# YT9215 register map
Vendor: Motorcomm; Series: YT921x; File version: 1.0
Registers are 32-bit, read-write, no defined reset value unless marked. A register's access mark holds for its fields unless they carry their own. Offsets are from the block's base; [hi:lo] are bit positions; lines under a group give offsets from that group; {n}, {i} and the like mark numbered series; 'fields as' and 'values as' point back to an identical list.

## L2 — Layer 2 forwarding and VLAN table
Base 0x00180000
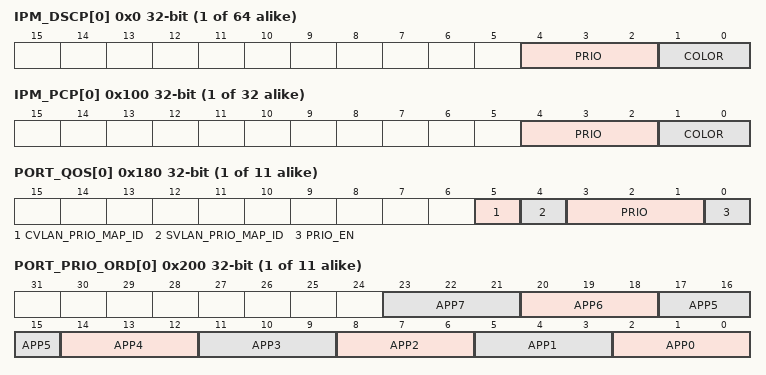
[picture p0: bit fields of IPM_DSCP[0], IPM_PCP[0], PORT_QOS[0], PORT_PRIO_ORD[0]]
{0x0+4i} IPM_DSCP[{i}] (i=0..63) — Internal priority and colour for each of the 64 IP DSCP values. Index: dscp = 0 to 63.
  [4:2] PRIO — Internal priority from 0 to 7.
  [1:0] COLOR — Drop precedence colour. It is inferred from METER_CTRL.COLOR_BLIND that the meters use it.
    0=GREEN (Lowest drop precedence); 1=YELLOW; 2=RED (Highest drop precedence)
{0x100+4i} IPM_PCP[{i}] (i=0..31) — Internal priority and colour for each VLAN tag priority. There are two maps (index map); each has one entry per drop eligible bit value (dei) and priority code point (pcp). The vendor SDK functions fal_tiger_qos_intPri_cpri_map_set() and fal_tiger_qos_intPri_spri_map_set() write a fixed map number to PORT_QOS and use it as the index map: 0 for the customer tag and 1 for the service tag. Index: map = 0 to 1, dei = 0 to 1, pcp = 0 to 7. Flat index = 16 × map + 8 × dei + pcp.
  fields as IPM_DSCP[0]
{0x180+4i} PORT_QOS[{i}] (i=0..10) — Port default priority and, by the code of the vendor SDK that the description of IPM_PCP names, the choice of IPM_PCP map. Index: port = 0 to 10.
  [5] CVLAN_PRIO_MAP_ID — Index map of the IPM_PCP map used for customer tags.
  [4] SVLAN_PRIO_MAP_ID — Index map of the IPM_PCP map used for service tags.
  [3:1] PRIO — Port default priority from 0 to 7.
  [0] PRIO_EN — Enables the port default priority.
{0x200+4i} PORT_PRIO_ORD[{i}] (i=0..10) — Ranks the sources of a frame's internal priority on one port. Each source has a 3-bit weight. It is inferred that the source with the highest non-zero weight that applies to the frame wins; a comment in yt_qos.h of the vendor SDK reads "The higher the value, the higher the priority". Priority sources lists the source numbers. Index: port = 0 to 10.
  [3n+2:3n] APP{n} (n=0..7) — Weight of priority source app. 0 disables the source, except for the port default priority which is enabled by PORT_QOS.PRIO_EN.
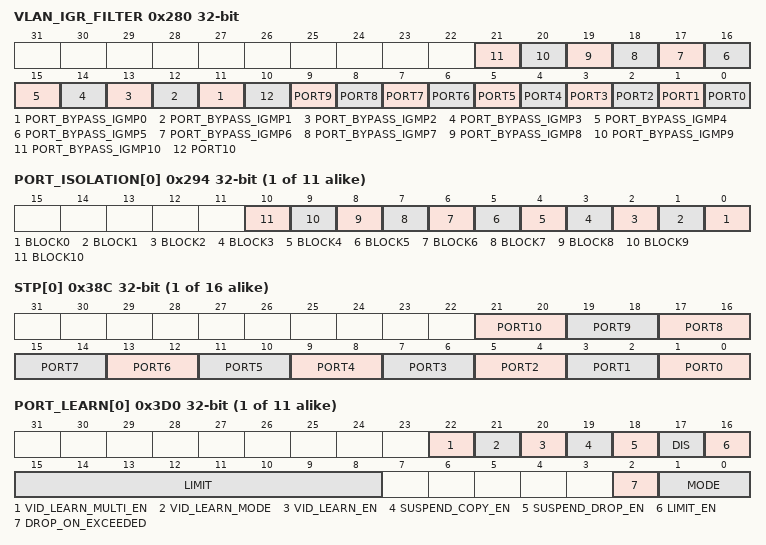
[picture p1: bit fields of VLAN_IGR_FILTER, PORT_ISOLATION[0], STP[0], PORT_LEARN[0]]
0x280 VLAN_IGR_FILTER — Per-port ingress VLAN membership check.
  [n+11] PORT_BYPASS_IGMP{n} (n=0..10) — IGMP frames received on port port skip the ingress membership check.
  [n] PORT{n} (n=0..10) — Port port receives frames only of VLANs that list it.
{0x294+4i} PORT_ISOLATION[{i}] (i=0..10) — Destination ports that frames received on one port must not be sent to. This is the mechanism that separates ports into groups; see Port isolation. Index: port = 0 to 10.
  [n] BLOCK{n} (n=0..10) — Frames received on this port are never sent to port port.
{0x38C+4i} STP[{i}] (i=0..15) — Port states of one spanning tree instance, two bits per port. A VLAN chooses its instance with VLAN_CTRL.STP_ID. Index: inst = 0 to 15.
  [2n+1:2n] PORT{n} (n=0..10) — State of port port in this instance.
    0=DISABLED (Port neither forwards nor learns); 1=LEARNING (Port learns addresses but does not forward); 2=BLOCKING (Port neither forwards nor learns. It is inferred from IEEE 802.1D that the port receives bridge protocol frames); 3=FORWARD (Port forwards and learns)
{0x3D0+4i} PORT_LEARN[{i}] (i=0..10) — Controls learning of source addresses on one port. Index: port = 0 to 10.
  [22] VID_LEARN_MULTI_EN — Function not known.
  [21] VID_LEARN_MODE — Function not known.
  [20] VID_LEARN_EN — Function not known.
  [19] SUSPEND_COPY_EN — Copy frames with a not yet learned source address to the CPU.
  [18] SUSPEND_DROP_EN — Drop frames with a not yet learned source address.
  [17] DIS — Disables address learning on the port.
  [16] LIMIT_EN — Enables the limit in PORT_LEARN.LIMIT.
  [15:8] LIMIT — Largest number of addresses learned on the port. The vendor SDK lists this field as 13 bits wide, at bits 15 to 3.
  [2] DROP_ON_EXCEEDED — Drop frames with a new source address once the limit is reached.
  [1:0] MODE — Who learns addresses.
    0=AUTO (The switch learns by itself); 1=AUTO_AND_COPY (The switch learns and copies the frame to the CPU); 2=CPU_CONTROL (Only the CPU adds entries)
0x440 AGEING — Time base of forwarding database ageing.
  [15:0] INTERVAL — Ageing time in units of 5 seconds.
0x454 FDB_IN0 — First input word of a forwarding database command; see Forwarding database.
  [31:0] ADDR_HI4 — MAC address bytes 0 to 3. Byte 0 is in bits 31 to 24.
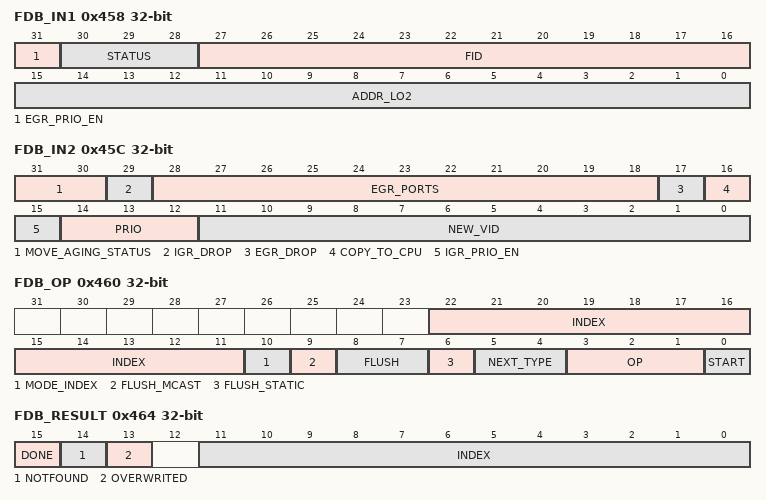
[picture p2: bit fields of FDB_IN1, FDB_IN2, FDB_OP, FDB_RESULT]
0x458 FDB_IN1 — Second input word of a forwarding database command.
  [31] EGR_PRIO_EN — Apply the priority of the entry to frames sent to this address.
  [30:28] STATUS — State of the entry.
    0=INVALID (Entry is empty); 1=MIN_TIME (Dynamic entry about to age out); 3=MOVE_AGING_MAX_TIME (Dynamic entry that moved to another port); 5=MAX_TIME (Dynamic entry just learned or refreshed); 6=PENDING (Entry waiting for the CPU to confirm it); 7=STATIC (Static entry that never ages out)
  [27:16] FID — Filtering ID of the entry. The Linux driver uses the VLAN ID as the filtering ID.
  [15:0] ADDR_LO2 — MAC address bytes 4 and 5. Byte 4 is in bits 15 to 8.
0x45C FDB_IN2 — Third input word of a forwarding database command.
  [31:30] MOVE_AGING_STATUS — Ageing state of an entry that moved between ports.
  [29] IGR_DROP — Drop frames received from this address.
  [28:18] EGR_PORTS — Ports that frames to this address are sent to. Each port has one bit.
  [17] EGR_DROP — Drop frames sent to this address.
  [16] COPY_TO_CPU — Also copy frames to this address to the CPU.
  [15] IGR_PRIO_EN — Apply FDB_IN2.PRIO to frames received from this address.
  [14:12] PRIO — Priority given by this entry. It is a source for PORT_PRIO_ORD.
  [11:0] NEW_VID — Replacement VLAN ID for frames matching the entry.
0x460 FDB_OP — Selects and starts a forwarding database command. Write the input words first, then this register with FDB_OP.START set, then wait for FDB_RESULT.DONE.
  [22:11] INDEX — Entry index from 0 to 4095. It is used when FDB_OP.MODE_INDEX is set.
  [10] MODE_INDEX — Addresses the entry by FDB_OP.INDEX. Value 0 addresses it by MAC address and filtering ID.
  [9] FLUSH_MCAST — A flush removes multicast entries in place of unicast entries. The vendor SDK list yt_l2_tbl_op_flush_mode_t gives this meaning to the bit.
  [8:7] FLUSH — Scope of a flush.
    0=ALL (Every entry of the kind that FDB_OP.FLUSH_MCAST selects); 1=PORT (Entries of the ports in FDB_IN2.EGR_PORTS); 2=PORT_VID (Entries of the ports in FDB_IN2.EGR_PORTS with the filtering ID in FDB_IN1.FID); 3=VID (Entries with the filtering ID in FDB_IN1.FID)
  [6] FLUSH_STATIC — A flush also removes static entries.
  [5:4] NEXT_TYPE — Which entries FDB_OP.OP.GET_NEXT walks.
    0=UCAST_PORT (Unicast entries of one port); 1=UCAST_VID (Unicast entries of one filtering ID); 2=UCAST (All unicast entries); 3=MCAST (Multicast entries)
  [3:1] OP — Command.
    0=ADD (Write an entry); 1=DEL (Delete an entry); 2=GET_ONE (Read one entry); 3=GET_NEXT (Read the next used entry after FDB_OP.INDEX); 4=FLUSH (Delete many entries)
  [0] START — Write 1 to start the command.
0x464 FDB_RESULT ro — Completion flag and outcome of the last FDB_OP command.
  [15] DONE — 1 when the command has finished.
  [14] NOTFOUND — No entry matched.
  [13] OVERWRITED — The command overwrote an existing entry.
  [11:0] INDEX — Index of the entry the command acted on.
0x4B0 FDB_OUT0 ro — First word of the entry read by a FDB_OP.OP.GET_ONE or FDB_OP.OP.GET_NEXT command.
  fields as FDB_IN0
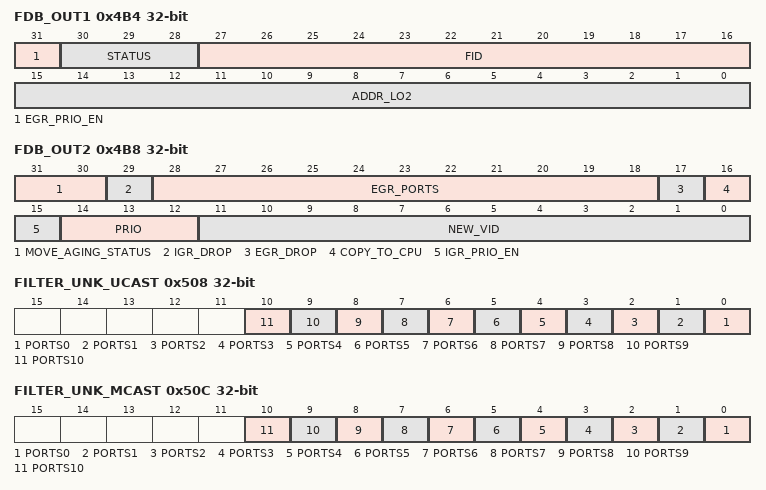
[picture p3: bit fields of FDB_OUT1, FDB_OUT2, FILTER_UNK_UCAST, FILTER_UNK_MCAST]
0x4B4 FDB_OUT1 ro — Second word of the entry read by a FDB_OP.OP.GET_ONE or FDB_OP.OP.GET_NEXT command.
  fields as FDB_IN1
0x4B8 FDB_OUT2 ro — Third word of the entry read by a FDB_OP.OP.GET_ONE or FDB_OP.OP.GET_NEXT command.
  [31:30] MOVE_AGING_STATUS — Ageing state of an entry that moved between ports.
  [29] IGR_DROP — Drop frames received from this address.
  [28:18] EGR_PORTS — Ports that frames to this address are sent to. Each port has one bit.
  [17] EGR_DROP — Drop frames sent to this address.
  [16] COPY_TO_CPU — Also copy frames to this address to the CPU.
  [15] IGR_PRIO_EN — Apply FDB_OUT2.PRIO to frames received from this address.
  [14:12] PRIO — Priority given by this entry. It is a source for PORT_PRIO_ORD.
  [11:0] NEW_VID — Replacement VLAN ID for frames matching the entry.
0x508 FILTER_UNK_UCAST — Port mask for flooded frames with an unknown unicast destination. yt921x_chip_setup_dsa sets the bit of every port.
  [n] PORTS{n} (n=0..10) — It is inferred from the word "filter" in the register name that frames of this class are not flooded to port port while its bit is set.
0x50C FILTER_UNK_MCAST — Port mask for flooded frames with an unknown multicast destination. yt921x_chip_setup_dsa sets the bit of every port.
  fields as FILTER_UNK_UCAST
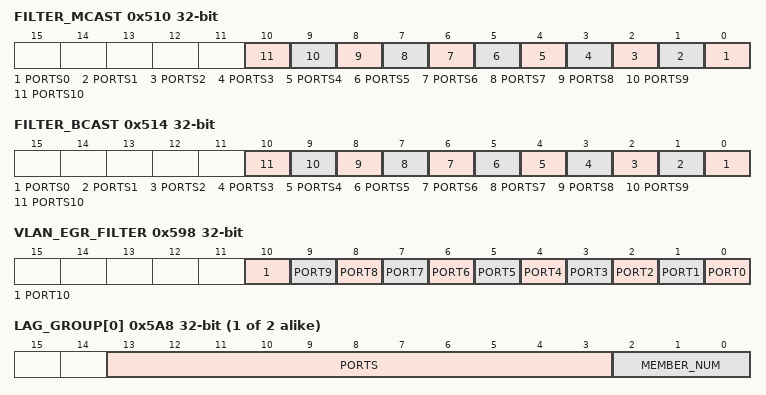
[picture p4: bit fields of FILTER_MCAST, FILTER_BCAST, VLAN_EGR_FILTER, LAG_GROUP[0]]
0x510 FILTER_MCAST — Ports that do not receive multicast frames.
  fields as FILTER_UNK_UCAST
0x514 FILTER_BCAST — Ports that do not receive broadcast frames.
  fields as FILTER_UNK_UCAST
0x598 VLAN_EGR_FILTER — Per-port egress VLAN membership check.
  [n] PORT{n} (n=0..10) — Port port sends frames only of VLANs that list it.
{0x5A8+4i} LAG_GROUP[{i}] (i=0..1) — Member ports and member count of one link aggregation group. Index: lag = 0 to 1.
  [13:3] PORTS — Member ports. Each port has one bit.
  [2:0] MEMBER_NUM — Number of valid LAG_MEMBER slots of the group.
{0x5B0+4i} LAG_MEMBER[{i}] (i=0..7) — Port in one of the four member slots of a group. The hash result picks a slot. Index: lag = 0 to 1, slot = 0 to 3. Flat index = 4 × lag + slot.
  [3:0] PORT — Port number in this slot.
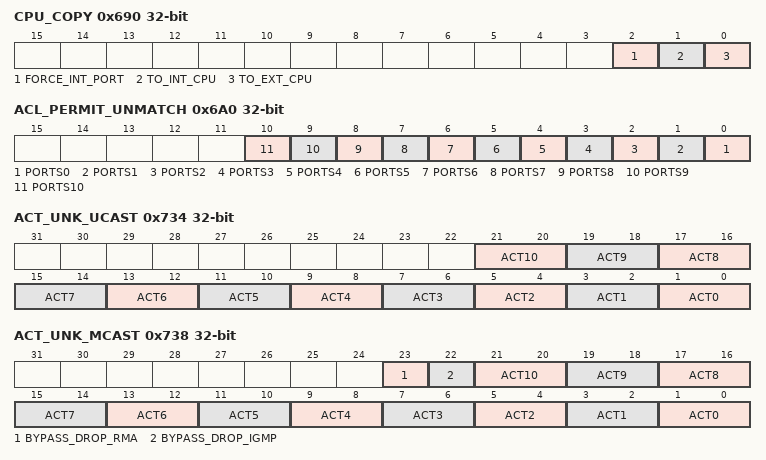
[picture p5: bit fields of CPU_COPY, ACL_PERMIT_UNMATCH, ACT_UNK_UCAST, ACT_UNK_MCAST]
0x690 CPU_COPY — Chooses where frames that are trapped or copied to the CPU go.
  [2] FORCE_INT_PORT — Always send such frames to the built-in microcontroller port.
  [1] TO_INT_CPU — Send such frames to the built-in microcontroller on port 10.
  [0] TO_EXT_CPU — Send such frames to the external CPU port set in EXT_CPU_PORT.
0x6A0 ACL_PERMIT_UNMATCH — Port mask for frames that match no ACL rule. yt921x_chip_setup_acl sets the bit of every port.
  [n] PORTS{n} (n=0..10) — yt921x_chip_setup_acl sets the bit of every port. It is inferred from the register name that port port then forwards received frames that match no rule.
0x734 ACT_UNK_UCAST — What the switch does with a frame whose unicast destination is not in the forwarding database, chosen per receiving port.
  [2n+1:2n] ACT{n} (n=0..10) — Action for frames received on port port.
    0=FORWARD (Flood the frame); 1=TRAP (Send the frame to the CPU only); 2=DROP (Discard the frame); 3=COPY (Flood the frame and copy it to the CPU)
0x738 ACT_UNK_MCAST — What the switch does with a frame whose multicast destination is not in the forwarding database, chosen per receiving port.
  [23] BYPASS_DROP_RMA — Reserved multicast addresses are exempt from the action ACT_UNK_MCAST.ACT.DROP.
  [22] BYPASS_DROP_IGMP — IGMP frames are exempt from the action ACT_UNK_MCAST.ACT.DROP.
  [2n+1:2n] ACT{n} (n=0..10) — Action for frames received on port port.
    values as ACT_UNK_UCAST.ACT0
0x958 FDB_HW_FLUSH — Lets the switch remove learned addresses on its own.
  [0] ON_LINKDOWN — Remove the dynamic entries of a port when its link goes down.
{0x8000+8i} VLAN_CTRL[{i}] (i=0..4095) group — One 64-bit entry per VLAN ID. Write the low word, then the high word. VLAN table shows how to build an entry. Index: vid = 0 to 4095.
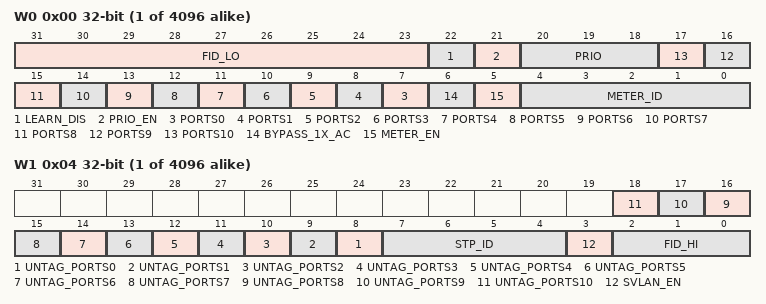
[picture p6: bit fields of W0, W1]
  0x00 W0 — VLAN table entry: bits 31 to 0. One 64-bit entry per VLAN ID. Write the low word, then the high word. VLAN table shows how to build an entry.
    [31:23] FID_LO — Filtering ID for address learning and lookup. No function of the Linux driver writes it. yt921x_fdb_in01 writes the VLAN ID to FDB_IN1.FID, so the Linux driver addresses the forwarding database by VLAN ID. The vendor SDK function fal_tiger_vlan_fid_set() writes the field, and the comment on yt_vlan_svlMode_enable_set() states that the lookup uses the filtering ID once VLAN_CTRL.SVLAN_EN is set. The field crosses the boundary between the two words.
    [22] LEARN_DIS — Source addresses of frames in this VLAN are not learned.
    [21] PRIO_EN — Frames of this VLAN get the priority in VLAN_CTRL.PRIO.
    [20:18] PRIO — VLAN priority. It is a source for PORT_PRIO_ORD.
    [n+7] PORTS{n} (n=0..10) — Member ports. Each port has one bit.
    [6] BYPASS_1X_AC — Frames of this VLAN skip IEEE 802.1X access control.
    [5] METER_EN — Frames of this VLAN are rate limited by the meter in VLAN_CTRL.METER_ID. The vendor SDK function fal_tiger_rate_meter_vlan_enable_set() writes this bit and VLAN_CTRL.METER_ID to attach a meter to a VLAN.
    [4:0] METER_ID — Meter number. It is an index of METER_CTRL.
  0x04 W1 — VLAN table entry: bits 63 to 32. One 64-bit entry per VLAN ID. Write the low word, then the high word. VLAN table shows how to build an entry.
    [n+8] UNTAG_PORTS{n} (n=0..10) — Ports that send frames of this VLAN without a tag. Each port has one bit.
    [7:4] STP_ID — Spanning tree instance of this VLAN. It selects the STP register.
    [3] SVLAN_EN — No function of the Linux driver sets it, as the comment in yt921x_vlan_aware_set states. The Linux name reads as a service VLAN enable. The vendor SDK names the bit SVL_EN and sets it in fal_tiger_vlan_svlMode_enable_set(); the comment on yt_vlan_svlMode_enable_set() reads "Set vlan svl mode.It will look up fid after enable svl." By that comment the bit makes the VLAN use VLAN_CTRL.FID for the address lookup, which disagrees with the reading of the Linux name.
    [2:0] FID_HI — Filtering ID for address learning and lookup. No function of the Linux driver writes it. yt921x_fdb_in01 writes the VLAN ID to FDB_IN1.FID, so the Linux driver addresses the forwarding database by VLAN ID. The vendor SDK function fal_tiger_vlan_fid_set() writes the field, and the comment on yt_vlan_svlMode_enable_set() states that the lookup uses the filtering ID once VLAN_CTRL.SVLAN_EN is set. The field crosses the boundary between the two words.
